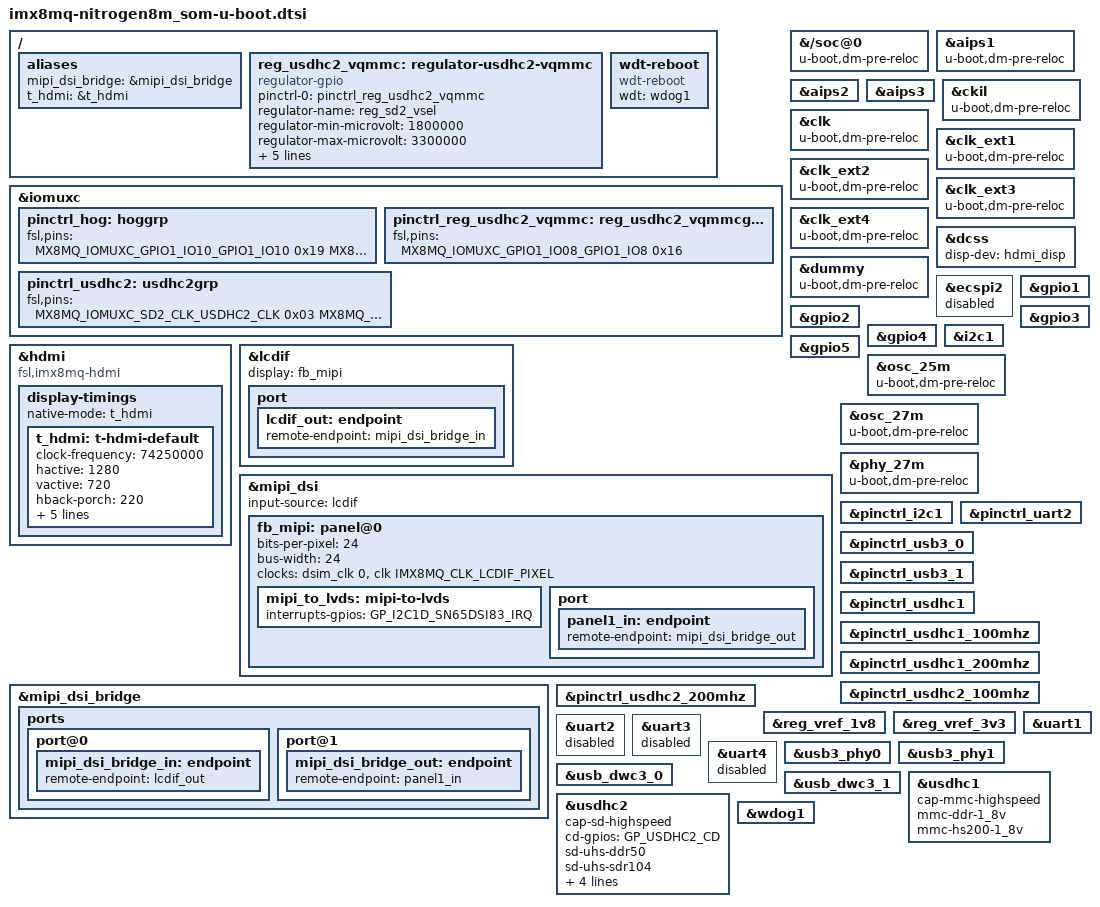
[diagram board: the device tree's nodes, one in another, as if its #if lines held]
// SPDX-License-Identifier: GPL-2.0+
/*
 * Copyright 2019 NXP
 */
#include "imx8mq-u-boot.dtsi"

#define GP_I2C1D_SN65DSI83_IRQ <&gpio1 1 GPIO_ACTIVE_HIGH>

&iomuxc {
#ifdef CONFIG_USDHC2_SD
	pinctrl_hog: hoggrp {
		fsl,pins = <
			/* J1 connector, odd */
			MX8MQ_IOMUXC_GPIO1_IO10_GPIO1_IO10		0x19	/* Pin 105 */
			MX8MQ_IOMUXC_GPIO1_IO05_GPIO1_IO5		0x19	/* Pin 143 */
			MX8MQ_IOMUXC_GPIO1_IO03_GPIO1_IO3		0x19	/* Pin 145 */
			MX8MQ_IOMUXC_NAND_CE3_B_GPIO3_IO4		0x19	/* Pin 149 */
			MX8MQ_IOMUXC_NAND_READY_B_GPIO3_IO16		0x19	/* Pin 153 */
			MX8MQ_IOMUXC_NAND_DATA05_GPIO3_IO11		0x19	/* Pin 155 */
			MX8MQ_IOMUXC_NAND_WP_B_GPIO3_IO18		0x19	/* Pin 157 */

			/* J1 connector, even */
			MX8MQ_IOMUXC_NAND_DATA04_GPIO3_IO10		0x19	/* Pin 82 */
			MX8MQ_IOMUXC_NAND_DATA03_GPIO3_IO9		0x19	/* Pin 84 */
			MX8MQ_IOMUXC_NAND_DATA02_GPIO3_IO8		0x19	/* Pin 86 */
			MX8MQ_IOMUXC_NAND_DATA01_GPIO3_IO7		0x19	/* Pin 88 */
			MX8MQ_IOMUXC_NAND_DATA00_GPIO3_IO6		0x19	/* Pin 90 */
			MX8MQ_IOMUXC_NAND_CE0_B_GPIO3_IO1		0x19	/* Pin 92 */
			MX8MQ_IOMUXC_NAND_ALE_GPIO3_IO0			0x19	/* Pin 96 */
			MX8MQ_IOMUXC_SAI1_TXD1_GPIO4_IO13		0x19	/* Pin 132 */
			MX8MQ_IOMUXC_SAI1_TXD2_GPIO4_IO14		0x19	/* Pin 134 */
			MX8MQ_IOMUXC_SAI1_TXD3_GPIO4_IO15		0x19	/* Pin 136 */
			MX8MQ_IOMUXC_SAI1_TXD4_GPIO4_IO16		0x19	/* Pin 138 */
			MX8MQ_IOMUXC_SAI1_TXD5_GPIO4_IO17		0x19	/* Pin 140 */
			MX8MQ_IOMUXC_SAI1_TXD6_GPIO4_IO18		0x19	/* Pin 142 */
			MX8MQ_IOMUXC_SAI1_TXD7_GPIO4_IO19		0x19	/* Pin 144 */
			MX8MQ_IOMUXC_SAI1_RXD1_GPIO4_IO3		0x19	/* Pin 146 */
			MX8MQ_IOMUXC_SAI1_RXD2_GPIO4_IO4		0x19	/* Pin 148 */
			MX8MQ_IOMUXC_SAI1_RXD3_GPIO4_IO5		0x19	/* Pin 150 */
			MX8MQ_IOMUXC_SAI1_RXD4_GPIO4_IO6		0x19	/* Pin 152 */
			MX8MQ_IOMUXC_SAI1_RXD5_GPIO4_IO7		0x19	/* Pin 154 */
			MX8MQ_IOMUXC_SAI1_RXD6_GPIO4_IO8		0x19	/* Pin 156 */
			MX8MQ_IOMUXC_SAI1_RXD7_GPIO4_IO9		0x19	/* Pin 158 */
			MX8MQ_IOMUXC_SAI1_RXC_GPIO4_IO1			0x19	/* Pin 160 */
			MX8MQ_IOMUXC_SAI1_RXFS_GPIO4_IO0		0x19	/* Pin 162 */
			MX8MQ_IOMUXC_SAI3_RXFS_GPIO4_IO28		0x19	/* Pin 198 */
			MX8MQ_IOMUXC_SAI3_RXC_GPIO4_IO29		0x19	/* Pin 200 */

			/* J13 Pin 2, BT_FUNC5 (TiWI only) */
			MX8MQ_IOMUXC_SAI5_RXD2_GPIO3_IO23		0xd6
			/* J13 Pin 4, WL_IRQ, not needed for Silex */
			MX8MQ_IOMUXC_SAI5_RXD0_GPIO3_IO21		0xd6
			/* J13 Pin 41, BT_CLK_REQ */
			MX8MQ_IOMUXC_SAI5_RXD1_GPIO3_IO22		0xd6
			/* J13 Pin 42, BT_HOST_WAKE */
			MX8MQ_IOMUXC_SAI5_MCLK_GPIO3_IO25		0xd6
			MX8MQ_IOMUXC_SPDIF_EXT_CLK_GPIO5_IO5		0x19	/* TP79 */
			MX8MQ_IOMUXC_GPIO1_IO08_GPIO1_IO8		0x49	/* TP80 */

			/* Clock for both CSI1 and CSI2 */
			MX8MQ_IOMUXC_GPIO1_IO15_CCMSRCGPCMIX_CLKO2	0x07
		>;
	};

	pinctrl_reg_usdhc2_vqmmc: reg_usdhc2_vqmmcgrp {
		fsl,pins = <
#define GP_USDHC2_VSEL	<&gpio1 8 GPIO_ACTIVE_HIGH>
			MX8MQ_IOMUXC_GPIO1_IO08_GPIO1_IO8		0x16
		>;
	};

	/delete-node/ reg-wlan-vmmcgrp;

	pinctrl_usdhc2: usdhc2grp {
		fsl,pins = <
			MX8MQ_IOMUXC_SD2_CLK_USDHC2_CLK			0x03
			MX8MQ_IOMUXC_SD2_CMD_USDHC2_CMD			0xc3
			MX8MQ_IOMUXC_SD2_DATA0_USDHC2_DATA0		0xc3
			MX8MQ_IOMUXC_SD2_DATA1_USDHC2_DATA1		0xc3
			MX8MQ_IOMUXC_SD2_DATA2_USDHC2_DATA2		0xc3
			MX8MQ_IOMUXC_SD2_DATA3_USDHC2_DATA3		0xc3
			/* Bluetooth slow clock */
			MX8MQ_IOMUXC_GPIO1_IO00_ANAMIX_REF_CLK_32K	0x03
#define GP_USDHC2_CD	<&gpio2 12 GPIO_ACTIVE_LOW>
			MX8MQ_IOMUXC_SD2_CD_B_GPIO2_IO12		0x41
		>;
	};
#endif
};

/ {
	aliases {
		mipi_dsi_bridge = &mipi_dsi_bridge;
		t_hdmi = &t_hdmi;
	};

#ifdef CONFIG_USDHC2_SD
	reg_usdhc2_vqmmc: regulator-usdhc2-vqmmc {
		compatible = "regulator-gpio";
		pinctrl-names = "default";
		pinctrl-0 = <&pinctrl_reg_usdhc2_vqmmc>;
		regulator-name = "reg_sd2_vsel";
		regulator-min-microvolt = <1800000>;
		regulator-max-microvolt = <3300000>;
		regulator-type = "voltage";
		regulator-boot-on;
		regulator-always-on;
		gpios = GP_USDHC2_VSEL;
		states = <1800000 0x1
			  3300000 0x0>;
	};

	/delete-node/ regulator-wlan-vmmc;
#endif

	wdt-reboot {
		compatible = "wdt-reboot";
		wdt = <&wdog1>;
		u-boot,dm-spl;
	};
};

&{/soc@0} {
	u-boot,dm-pre-reloc;
	u-boot,dm-spl;
};

&aips1 {
	u-boot,dm-spl;
	u-boot,dm-pre-reloc;
};

&aips2 {
	u-boot,dm-spl;
};

&aips3 {
	u-boot,dm-spl;
};

&ckil {
	u-boot,dm-spl;
	u-boot,dm-pre-reloc;
};

&clk {
	u-boot,dm-spl;
	u-boot,dm-pre-reloc;
	/delete-property/ assigned-clocks;
	/delete-property/ assigned-clock-parents;
	/delete-property/ assigned-clock-rates;
};

&clk_ext1 {
	u-boot,dm-spl;
	u-boot,dm-pre-reloc;
};

&clk_ext2 {
	u-boot,dm-spl;
	u-boot,dm-pre-reloc;
};

&clk_ext3 {
	u-boot,dm-spl;
	u-boot,dm-pre-reloc;
};

&clk_ext4 {
	u-boot,dm-spl;
	u-boot,dm-pre-reloc;
};

&dcss {
	disp-dev = "hdmi_disp";
};

&dummy {
	u-boot,dm-spl;
	u-boot,dm-pre-reloc;
};

&ecspi2 {
	status = "disabled";
};

&gpio1 {
	u-boot,dm-spl;
};

&gpio2 {
	u-boot,dm-spl;
};

&gpio3 {
	u-boot,dm-spl;
};

&gpio4 {
	u-boot,dm-spl;
};

&gpio5 {
	u-boot,dm-spl;
};

&hdmi {
	compatible = "fsl,imx8mq-hdmi";

	display-timings {
		native-mode = <&t_hdmi>;

		t_hdmi: t-hdmi-default {
			clock-frequency = <74250000>;
			hactive = <1280>;
			vactive = <720>;
			hback-porch = <220>;
			hfront-porch = <110>;
			hsync-len = <40>;
			vback-porch = <20>;
			vfront-porch = <5>;
			vsync-len = <5>;
		};
	};
};

&i2c1 {
	u-boot,dm-spl;
};

&iomuxc {
	u-boot,dm-spl;
};

&lcdif {
	display = <&fb_mipi>;
	status = "okay";

	/delete-node/ port;

	port {
		lcdif_out: endpoint {
			remote-endpoint = <&mipi_dsi_bridge_in>;
		};
	};
};

&mipi_dsi {
	input-source = "lcdif";

	fb_mipi: panel@0 {
		bits-per-pixel = <24>;
		bus-width = <24>;
		clocks = <&dsim_clk 0>,
			 <&clk IMX8MQ_CLK_LCDIF_PIXEL>;

		mipi_to_lvds: mipi-to-lvds {
			interrupts-gpios = GP_I2C1D_SN65DSI83_IRQ;
		};

		/delete-node/ port;
		port {
			panel1_in: endpoint {
				remote-endpoint = <&mipi_dsi_bridge_out>;
			};
		};
	};

	/delete-node/ ports;
};

&mipi_dsi_bridge {
	ports {
		#address-cells = <1>;
		#size-cells = <0>;

		port@0 {
			mipi_dsi_bridge_in: endpoint {
				remote-endpoint = <&lcdif_out>;
			};
		};

		port@1 {
			mipi_dsi_bridge_out: endpoint {
				remote-endpoint = <&panel1_in>;
			};
		};
	};
};

&osc_25m {
	u-boot,dm-spl;
	u-boot,dm-pre-reloc;
};

&osc_27m {
	u-boot,dm-spl;
	u-boot,dm-pre-reloc;
};

&phy_27m {
	u-boot,dm-spl;
	u-boot,dm-pre-reloc;
};

&pinctrl_i2c1 {
	u-boot,dm-spl;
};

&pinctrl_uart2 {
	u-boot,dm-spl;
};

&pinctrl_usb3_0 {
	u-boot,dm-spl;
};

&pinctrl_usb3_1 {
	u-boot,dm-spl;
};

&pinctrl_usdhc1 {
	u-boot,dm-spl;
};

&pinctrl_usdhc1_100mhz {
	u-boot,dm-spl;
};

&pinctrl_usdhc1_200mhz {
	u-boot,dm-spl;
};

&pinctrl_usdhc2 {
	u-boot,dm-spl;
};

&pinctrl_usdhc2_100mhz {
	u-boot,dm-spl;
};

&pinctrl_usdhc2_200mhz {
	u-boot,dm-spl;
};

&reg_vref_1v8 {
	u-boot,dm-spl;
};

&reg_vref_3v3 {
	u-boot,dm-spl;
};

&uart1 {
	u-boot,dm-spl;
};

&uart2 {
	status = "disabled";
};

&uart3 {
	status = "disabled";
};

&uart4 {
	status = "disabled";
};

&usb3_phy0 {
	u-boot,dm-spl;
};

&usb3_phy1 {
	u-boot,dm-spl;
};

&usb_dwc3_0 {
	u-boot,dm-spl;
};

&usb_dwc3_1 {
	u-boot,dm-spl;
};

&usdhc1 {
	cap-mmc-highspeed;
	mmc-ddr-1_8v;
	mmc-hs200-1_8v;
	u-boot,dm-spl;
};

&usdhc2 {
#ifdef CONFIG_USDHC2_SD
	cap-sd-highspeed;
	cd-gpios = GP_USDHC2_CD;
	/delete-property/ no-sd-uhs-sdr104;
	/delete-property/ pm-ignore-notify;
	/delete-property/ keep-power-in-suspend;
	/delete-property/ non-removable;
	sd-uhs-ddr50;
	sd-uhs-sdr104;
	sd-uhs-sdr12;
	sd-uhs-sdr25;
	vmmc-supply = <&reg_vref_3v3>;
	vqmmc-supply = <&reg_usdhc2_vqmmc>;
	/delete-property/ vqmmc-1-8-v;
#else
	status = "disabled";
#endif
	u-boot,dm-spl;
};

&wdog1 {
	u-boot,dm-spl;
};
